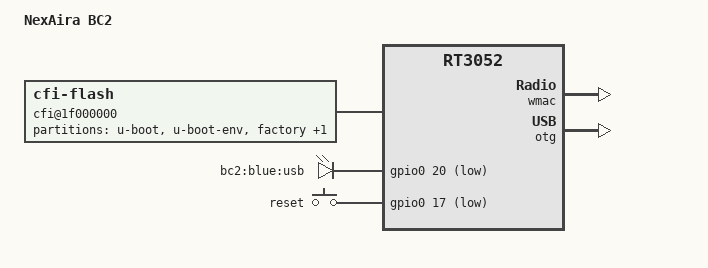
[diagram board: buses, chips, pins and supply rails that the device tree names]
/dts-v1/;

#include "rt3050.dtsi"

#include <dt-bindings/gpio/gpio.h>
#include <dt-bindings/input/input.h>

/ {
	compatible = "nexaira,bc2", "ralink,rt3052-soc";
	model = "NexAira BC2";

	cfi@1f000000 {
		compatible = "cfi-flash";
		reg = <0x1f000000 0x800000>;
		bank-width = <2>;
		device-width = <2>;

		partitions {
			compatible = "fixed-partitions";
			#address-cells = <1>;
			#size-cells = <1>;

			partition@0 {
				label = "u-boot";
				reg = <0x0 0x30000>;
				read-only;
			};

			partition@30000 {
				label = "u-boot-env";
				reg = <0x30000 0x10000>;
				read-only;
			};

			factory: partition@40000 {
				label = "factory";
				reg = <0x40000 0x10000>;
				read-only;
			};

			partition@50000 {
				compatible = "denx,uimage";
				label = "firmware";
				reg = <0x50000 0x7b0000>;
			};
		};
	};

	leds {
		compatible = "gpio-leds";

		usb {
			label = "bc2:blue:usb";
			gpios = <&gpio0 20 GPIO_ACTIVE_LOW>;
			trigger-sources = <&otg_port1>;
			linux,default-trigger = "usbport";
		};
	};

	keys {
		compatible = "gpio-keys-polled";
		poll-interval = <20>;

		reset {
			label = "reset";
			gpios = <&gpio0 17 GPIO_ACTIVE_LOW>;
			linux,code = <KEY_RESTART>;
		};
	};
};

&state_default {
	gpio {
		ralink,group = "spi", "i2c", "jtag", "rgmii", "mdio", "uartf";
		ralink,function = "gpio";
	};
};

&ethernet {
	mtd-mac-address = <&factory 0x4>;
};

&esw {
	mediatek,portmap = <0x2f>;
};

&wmac {
	ralink,mtd-eeprom = <&factory 0>;
};

&otg {
	status = "okay";
};
